# A31G33x register map
Vendor: VENDOR ABOV Semiconductor Co., Ltd.; Series: A31G33x; File version: 1.0
CPU: CM0+ r0p1, little endian, no MPU, no FPU, VTOR, 2 interrupt priority bits
Registers are 32-bit, read-only, no defined reset value unless marked. A register's access mark holds for its fields unless they carry their own. Offsets are from the block's base; [hi:lo] are bit positions; {n}, {i} and the like mark numbered series; 'fields as' and 'values as' point back to an identical list.

## PA — Port Control Unit & GPIO Port A
Base 0x30000000
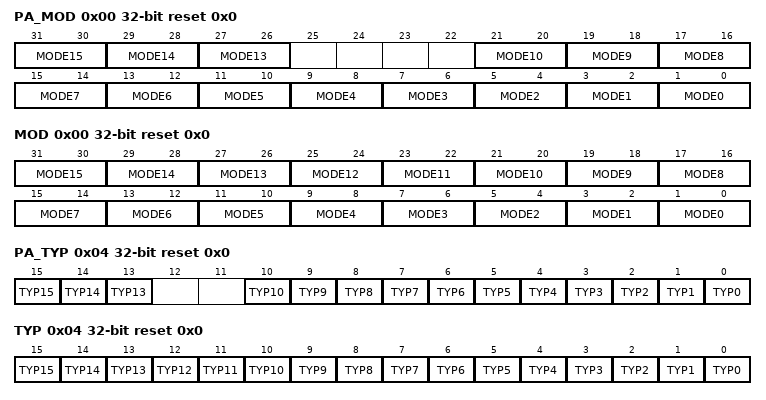
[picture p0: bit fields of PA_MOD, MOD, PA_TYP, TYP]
0x00 PA_MOD rw reset 0x0 (alternate view of MOD) — Port n Mode Register
  [31:30] MODE15 — Port n Mode Selection 15
  [29:28] MODE14 — Port n Mode Selection 14
  [27:26] MODE13 — Port n Mode Selection 13
  [2n+1:2n] MODE{n} (n=0..10) — Port n Mode Selection {n}
0x00 MOD rw reset 0x0 — Port n Mode Register
  [all] fields
    0=Input Mode; 1=Output Mode; 2=Alternative Function Mode
  [2n+1:2n] MODE{n} (n=0..15) — Port n Mode Selection {n}
0x04 PA_TYP rw reset 0x0 (alternate view of TYP) — Port n Output Type Selection Register
  [15] TYP15 — Port n Output Type Selection 15
  [14] TYP14 — Port n Output Type Selection 14
  [13] TYP13 — Port n Output Type Selection 13
  [n] TYP{n} (n=0..10) — Port n Output Type Selection {n}
0x04 TYP rw reset 0x0 — Port n Output Type Selection Register
  [all] fields
    0=Push-Pull Output; 1=Open-Drain Output
  [n] TYP{n} (n=0..15) — Port n Output Type Selection {n}
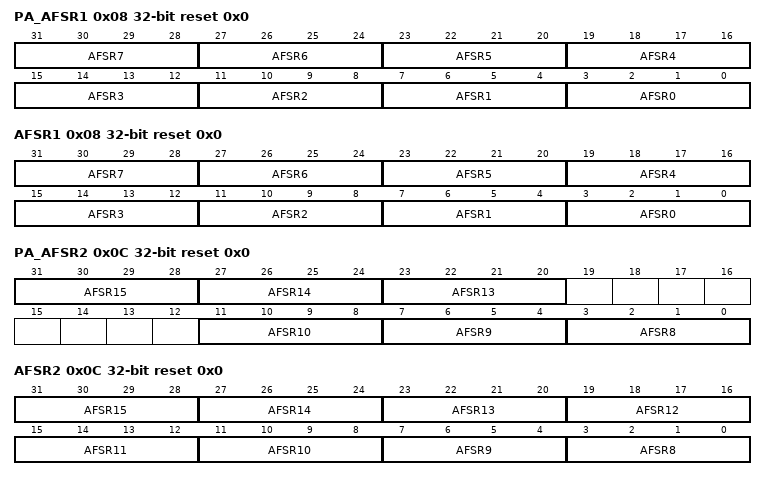
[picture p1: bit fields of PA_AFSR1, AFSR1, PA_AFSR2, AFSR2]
0x08 PA_AFSR1 rw reset 0x0 (alternate view of AFSR1) — Port n Alternative Function Selection Register 1
  [4n+3:4n] AFSR{n} (n=0..7) — Port n Alternative Function Selection {n}
0x08 AFSR1 rw reset 0x0 — Port n Alternative Function Selection Register 1
  [all] fields
    {v}=AF{v} (Alternative Function {v} (AF{v})) (v=0..7)
  [4n+3:4n] AFSR{n} (n=0..7) — Port n Alternative Function Selection {n}
0x0C PA_AFSR2 rw reset 0x0 (alternate view of AFSR2) — Port n Alternative Function Selection Register 2
  [31:28] AFSR15 — Port n Alternative Function Selection 15
  [27:24] AFSR14 — Port n Alternative Function Selection 14
  [23:20] AFSR13 — Port n Alternative Function Selection 13
  [11:8] AFSR10 — Port n Alternative Function Selection 10
  [7:4] AFSR9 — Port n Alternative Function Selection 9
  [3:0] AFSR8 — Port n Alternative Function Selection 8
0x0C AFSR2 rw reset 0x0 — Port n Alternative Function Selection Register 2
  [all] fields
    {v}=AF{v} (Alternative Function {v} (AF{v})) (v=0..7)
  [4n-29:4n-32] AFSR{n} (n=8..15) — Port n Alternative Function Selection {n}
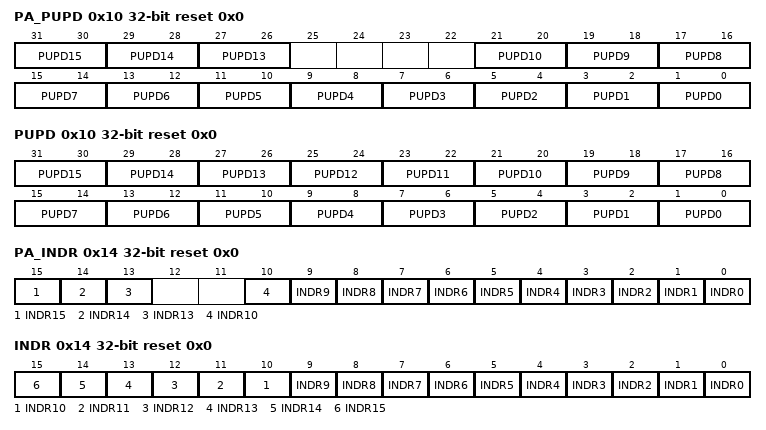
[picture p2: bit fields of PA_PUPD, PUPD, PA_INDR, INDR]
0x10 PA_PUPD rw reset 0x0 (alternate view of PUPD) — Port n Pull-Up/Down Resistor Selection Register
  [31:30] PUPD15 — Port n Pull-Up/Down Resistor Selection 15
  [29:28] PUPD14 — Port n Pull-Up/Down Resistor Selection 14
  [27:26] PUPD13 — Port n Pull-Up/Down Resistor Selection 13
  [2n+1:2n] PUPD{n} (n=0..10) — Port n Pull-Up/Down Resistor Selection {n}
0x10 PUPD rw reset 0x0 — Port n Pull-Up/Down Resistor Selection Register
  [all] fields
    0=Disable pull-up/down resistor; 1=Enable pull-up resistor; 2=EnablePD (Enable pull-down resistor.)
  [2n+1:2n] PUPD{n} (n=0..15) — Port n Pull-Up/Down Resistor Selection {n}
0x14 PA_INDR reset 0x0 (alternate view of INDR) — Port n Input Data Register
  [15] INDR15 — Port n Input Data 15
  [14] INDR14 — Port n Input Data 14
  [13] INDR13 — Port n Input Data 13
  [n] INDR{n} (n=0..10) — Port n Input Data {n}
0x14 INDR reset 0x0 — Port n Input Data Register
  [n] INDR{n} (n=0..15) — Port n Input Data {n}
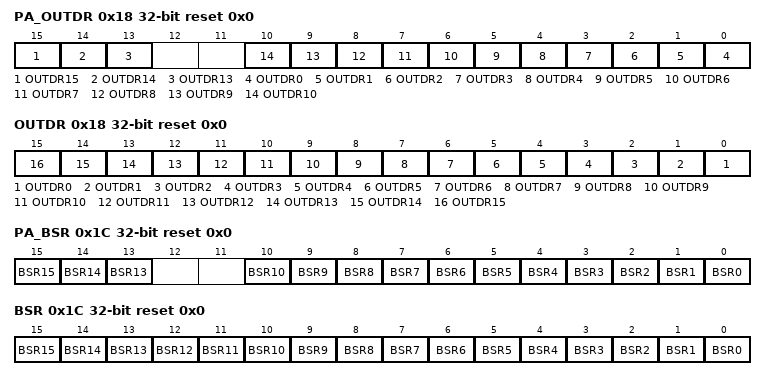
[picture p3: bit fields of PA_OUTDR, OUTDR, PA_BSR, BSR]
0x18 PA_OUTDR rw reset 0x0 (alternate view of OUTDR) — Port n Output Data Register
  [15] OUTDR15 — Port n Output Data 15
  [14] OUTDR14 — Port n Output Data 14
  [13] OUTDR13 — Port n Output Data 13
  [n] OUTDR{n} (n=0..10) — Port n Output Data {n}
0x18 OUTDR rw reset 0x0 — Port n Output Data Register
  [n] OUTDR{n} (n=0..15) — Port n Output Data {n}
0x1C PA_BSR wo reset 0x0 (alternate view of BSR) — Port n Output Bit Set Register
  [15] BSR15 — Port n Output Bit Set 15
  [14] BSR14 — Port n Output Bit Set 14
  [13] BSR13 — Port n Output Bit Set 13
  [n] BSR{n} (n=0..10) — Port n Output Bit Set {n}
0x1C BSR wo reset 0x0 — Port n Output Bit Set Register
  [all] fields
    0=NoEffect; 1=Set (Set the corresponding OUTDRx bit (Automatically cleared to 0.))
  [n] BSR{n} (n=0..15) — Port n Output Bit Set {n}
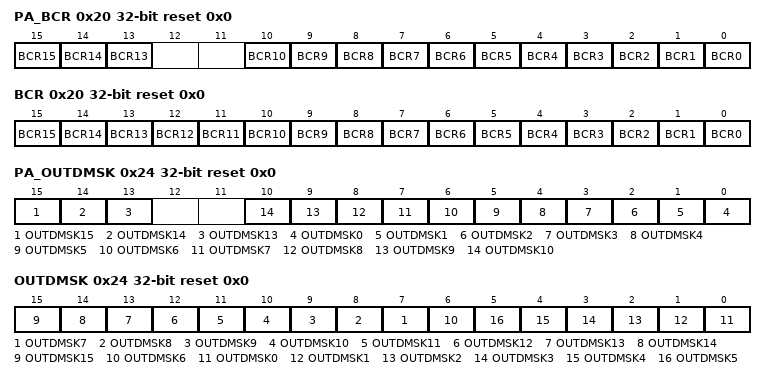
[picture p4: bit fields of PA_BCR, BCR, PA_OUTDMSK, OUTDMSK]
0x20 PA_BCR wo reset 0x0 (alternate view of BCR) — Port n Output Bit Clear Register
  [15] BCR15 — Port n Output Bit Clear 15
  [14] BCR14 — Port n Output Bit Clear 14
  [13] BCR13 — Port n Output Bit Clear 13
  [n] BCR{n} (n=0..10) — Port n Output Bit Clear {n}
0x20 BCR wo reset 0x0 — Port n Output Bit Clear Register
  [all] fields
    0=NoEffect; 1=Clear the corresponding OUTDRx bit. (Automatically cleared to 0.)
  [n] BCR{n} (n=0..15) — Port n Output Bit Clear {n}
0x24 PA_OUTDMSK rw reset 0x0 (alternate view of OUTDMSK) — Port n Output Data Mask Register
  [15] OUTDMSK15 — Port n Output Data Mask 15
  [14] OUTDMSK14 — Port n Output Data Mask 14
  [13] OUTDMSK13 — Port n Output Data Mask 13
  [n] OUTDMSK{n} (n=0..10) — Port n Output Data Mask {n}
0x24 OUTDMSK rw reset 0x0 — Port n Output Data Mask Register
  [n] OUTDMSK{n} (n=7..15) — Port n Output Data Mask {n}
    0=Unmask. The corresponding OUTDRx bit can be changed.; 1=Mask. The corresponding OUTDRx bit is protected.
  [6] OUTDMSK6 — Port n Output Data Mask 6
  [n] OUTDMSK{n} (n=0..5) — Port n Output Data Mask {n}
    values as OUTDMSK7
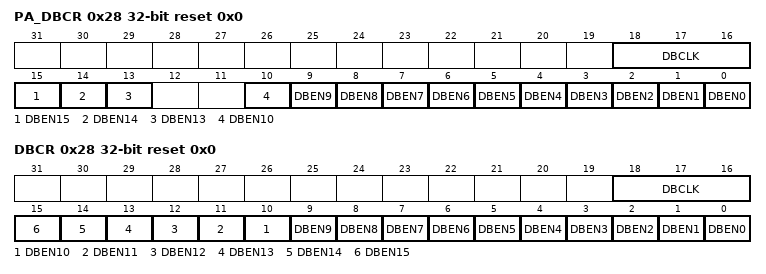
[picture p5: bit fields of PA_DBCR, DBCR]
0x28 PA_DBCR rw reset 0x0 (alternate view of DBCR) — Port n Debounce Control Register
  [18:16] DBCLK — Port n Debounce Filter Sampling Clock Selection
  [15] DBEN15 — Port n Debounce Enable 15
  [14] DBEN14 — Port n Debounce Enable 14
  [13] DBEN13 — Port n Debounce Enable 13
  [n] DBEN{n} (n=0..10) — Port n Debounce Enable {n}
0x28 DBCR rw reset 0x0 — Port n Debounce Control Register
  [18:16] DBCLK — Port n Debounce Filter Sampling Clock Selection
    0=HCLK1; 1=HCLK4; 2=HCLK16; 3=HCLK64; 4=HCLK256; 5=HCLK1024
  [n] DBEN{n} (n=0..15) — Port n Debounce Enable {n}
    0=Disable debounce filter; 1=Enable debounce filter
